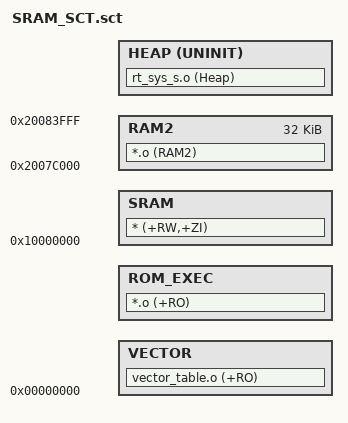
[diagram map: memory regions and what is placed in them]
ROM_LOAD 0x00000000
{
    VECTOR 0x00000000
    {
        vector_table.o (+RO)
    }
    ROM_EXEC +0
    {
        *.o (+RO)
    }

    SRAM 0x10000000
    {
        * (+RW,+ZI)
    }

	RAM2 0x2007C000 0x8000
	{
		*.o (RAM2)
	}

    HEAP +0 UNINIT
    {
        rt_sys_s.o (Heap)
    }
}
